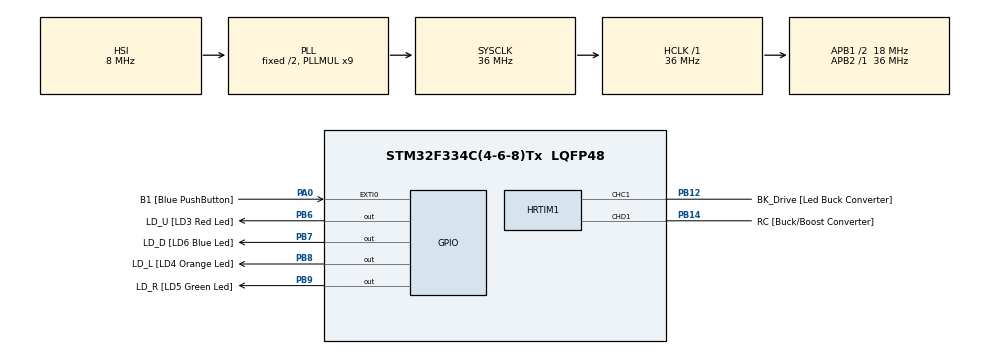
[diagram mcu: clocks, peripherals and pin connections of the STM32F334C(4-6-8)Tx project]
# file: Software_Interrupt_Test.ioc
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HRTIM1.DMARequests_Semaphore-Output_TC1=ATLEASTONEDMAREQ
HRTIM1.DMARequests_Semaphore-Output_TD1=ATLEASTONEDMAREQ
HRTIM1.Output1-Output_TC1=HRTIM_OUTPUT_TC1
HRTIM1.TimerIdx-Output_TC1=HRTIM_TIMERINDEX_TIMER_C
Mcu.Family=STM32F3
Mcu.Name=STM32F334C(4-6-8)Tx
Mcu.Package=LQFP48
NVIC.PriorityGroup=NVIC_PRIORITYGROUP_0
PA0.GPIO_Label=B1 [Blue PushButton]
PA0.GPIO_ModeDefaultEXTI=GPIO_MODE_EVT_RISING
PA0.GPIO_PuPd=GPIO_NOPULL
PA0.Signal=GPXTI0
PA13.GPIO_Label=SWDIO
PA13.Mode=Serial_Wire
PA13.Signal=SYS_JTMS-SWDIO
PA14.GPIO_Label=SWCLK
PA14.Mode=Serial_Wire
PA14.Signal=SYS_JTCK-SWCLK
PB12.GPIO_Label=BK_Drive [Led Buck Converter]
PB12.GPIO_ModeDefaultPP=GPIO_MODE_AF_PP
PB12.GPIO_PuPd=GPIO_NOPULL
PB12.GPIO_Speed=GPIO_SPEED_FREQ_LOW
PB12.Mode=Output_TC1
PB12.Signal=HRTIM1_CHC1
PB14.GPIO_Label=RC [Buck/Boost Converter]
PB14.Mode=Output_TD1
PB14.Signal=HRTIM1_CHD1
PB6.GPIO_FM6=__NULL
PB6.GPIO_Label=LD_U [LD3 Red Led]
PB6.GPIO_ModeDefaultOutputPP=GPIO_MODE_OUTPUT_PP
PB6.GPIO_PuPd=GPIO_NOPULL
PB6.GPIO_Speed=GPIO_SPEED_FREQ_LOW
PB6.Signal=GPIO_Output
PB7.GPIO_FM7=__NULL
PB7.GPIO_Label=LD_D [LD6 Blue Led]
PB7.GPIO_ModeDefaultOutputPP=GPIO_MODE_OUTPUT_PP
PB7.GPIO_PuPd=GPIO_NOPULL
PB7.GPIO_Speed=GPIO_SPEED_FREQ_LOW
PB7.Signal=GPIO_Output
PB8.GPIO_FM8=__NULL
PB8.GPIO_Label=LD_L [LD4 Orange Led]
PB8.GPIO_ModeDefaultOutputPP=GPIO_MODE_OUTPUT_PP
PB8.GPIO_PuPd=GPIO_NOPULL
PB8.GPIO_Speed=GPIO_SPEED_FREQ_LOW
PB8.Signal=GPIO_Output
PB9.GPIO_FM9=__NULL
PB9.GPIO_Label=LD_R [LD5 Green Led]
PB9.GPIO_ModeDefaultOutputPP=GPIO_MODE_OUTPUT_PP
PB9.GPIO_PuPd=GPIO_NOPULL
PB9.GPIO_Speed=GPIO_SPEED_FREQ_LOW
PB9.Signal=GPIO_Output
ProjectManager.HeapSize=0x200
ProjectManager.StackSize=0x400
ProjectManager.TargetToolchain=Makefile
RCC.AHBFreq_Value=36000000
RCC.APB1CLKDivider=RCC_HCLK_DIV2
RCC.APB1Freq_Value=18000000
RCC.APB1TimFreq_Value=36000000
RCC.APB2Freq_Value=36000000
RCC.APB2TimFreq_Value=36000000
RCC.CortexFreq_Value=36000000
RCC.HCLKFreq_Value=36000000
RCC.HSE_VALUE=8000000
RCC.HSI_VALUE=8000000
RCC.LSE_VALUE=32768
RCC.PLLMUL=RCC_PLL_MUL9
RCC.SYSCLKFreq_VALUE=36000000
RCC.SYSCLKSourceVirtual=RCC_SYSCLKSOURCE_PLLCLK
board=32F3348DISCOVERY

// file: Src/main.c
/* USER CODE BEGIN Header */
/**
  ******************************************************************************
  * @file           : main.c
  * @brief          : Main program body
  ******************************************************************************
  ** This notice applies to any and all portions of this file
  * that are not between comment pairs USER CODE BEGIN and
  * USER CODE END. Other portions of this file, whether
  * inserted by the user or by software development tools
  * are owned by their respective copyright owners.
  *
  * COPYRIGHT(c) 2019 STMicroelectronics
  *
  * Redistribution and use in source and binary forms, with or without modification,
  * are permitted provided that the following conditions are met:
  *   1. Redistributions of source code must retain the above copyright notice,
  *      this list of conditions and the following disclaimer.
  *   2. Redistributions in binary form must reproduce the above copyright notice,
  *      this list of conditions and the following disclaimer in the documentation
  *      and/or other materials provided with the distribution.
  *   3. Neither the name of STMicroelectronics nor the names of its contributors
  *      may be used to endorse or promote products derived from this software
  *      without specific prior written permission.
  *
  * THIS SOFTWARE IS PROVIDED BY THE COPYRIGHT HOLDERS AND CONTRIBUTORS "AS IS"
  * AND ANY EXPRESS OR IMPLIED WARRANTIES, INCLUDING, BUT NOT LIMITED TO, THE
  * IMPLIED WARRANTIES OF MERCHANTABILITY AND FITNESS FOR A PARTICULAR PURPOSE ARE
  * DISCLAIMED. IN NO EVENT SHALL THE COPYRIGHT HOLDER OR CONTRIBUTORS BE LIABLE
  * FOR ANY DIRECT, INDIRECT, INCIDENTAL, SPECIAL, EXEMPLARY, OR CONSEQUENTIAL
  * DAMAGES (INCLUDING, BUT NOT LIMITED TO, PROCUREMENT OF SUBSTITUTE GOODS OR
  * SERVICES; LOSS OF USE, DATA, OR PROFITS; OR BUSINESS INTERRUPTION) HOWEVER
  * CAUSED AND ON ANY THEORY OF LIABILITY, WHETHER IN CONTRACT, STRICT LIABILITY,
  * OR TORT (INCLUDING NEGLIGENCE OR OTHERWISE) ARISING IN ANY WAY OUT OF THE USE
  * OF THIS SOFTWARE, EVEN IF ADVISED OF THE POSSIBILITY OF SUCH DAMAGE.
  *
  ******************************************************************************
  */
/* USER CODE END Header */

#include "main.h"

HRTIM_HandleTypeDef hhrtim1;

void SystemClock_Config(void);
static void MX_GPIO_Init(void);
static void MX_HRTIM1_Init(void);
static void EXTI1_Init(void);

int main(void)
{

  /* MCU Configuration--------------------------------------------------------*/

  /* Reset of all peripherals, Initializes the Flash interface and the Systick. */
  HAL_Init();
  EXTI1_Init();

  /* Configure the system clock */
  SystemClock_Config();

  /* Initialize all configured peripherals */
  MX_GPIO_Init();
  MX_HRTIM1_Init();

  /* Infinite loop */
  /* USER CODE BEGIN WHILE */
  while (1)
  {
    //Triggers the External Interrupt on line 1, which takes us to the interrupt handler.
    NVIC->STIR = EXTI1_IRQn;
    HAL_GPIO_TogglePin(GPIOB,LD_D_Pin);
    HAL_Delay(500);
  }
  /* USER CODE END 3 */
}

void SystemClock_Config(void)
{
  RCC_OscInitTypeDef RCC_OscInitStruct = {0};
  RCC_ClkInitTypeDef RCC_ClkInitStruct = {0};
  RCC_PeriphCLKInitTypeDef PeriphClkInit = {0};

  /**Initializes the CPU, AHB and APB busses clocks
  */
  RCC_OscInitStruct.OscillatorType = RCC_OSCILLATORTYPE_HSI;
  RCC_OscInitStruct.HSIState = RCC_HSI_ON;
  RCC_OscInitStruct.HSICalibrationValue = RCC_HSICALIBRATION_DEFAULT;
  RCC_OscInitStruct.PLL.PLLState = RCC_PLL_ON;
  RCC_OscInitStruct.PLL.PLLSource = RCC_PLLSOURCE_HSI;
  RCC_OscInitStruct.PLL.PLLMUL = RCC_PLL_MUL9;
  if (HAL_RCC_OscConfig(&RCC_OscInitStruct) != HAL_OK)
  {
    Error_Handler();
  }
  /**Initializes the CPU, AHB and APB busses clocks
  */
  RCC_ClkInitStruct.ClockType = RCC_CLOCKTYPE_HCLK|RCC_CLOCKTYPE_SYSCLK
                              |RCC_CLOCKTYPE_PCLK1|RCC_CLOCKTYPE_PCLK2;
  RCC_ClkInitStruct.SYSCLKSource = RCC_SYSCLKSOURCE_PLLCLK;
  RCC_ClkInitStruct.AHBCLKDivider = RCC_SYSCLK_DIV1;
  RCC_ClkInitStruct.APB1CLKDivider = RCC_HCLK_DIV2;
  RCC_ClkInitStruct.APB2CLKDivider = RCC_HCLK_DIV1;

  if (HAL_RCC_ClockConfig(&RCC_ClkInitStruct, FLASH_LATENCY_1) != HAL_OK)
  {
    Error_Handler();
  }
  PeriphClkInit.PeriphClockSelection = RCC_PERIPHCLK_HRTIM1;
  PeriphClkInit.Hrtim1ClockSelection = RCC_HRTIM1CLK_HCLK;
  if (HAL_RCCEx_PeriphCLKConfig(&PeriphClkInit) != HAL_OK)
  {
    Error_Handler();
  }
}

static void MX_HRTIM1_Init(void)
{

  HRTIM_TimeBaseCfgTypeDef pTimeBaseCfg = {0};
  HRTIM_TimerCfgTypeDef pTimerCfg = {0};
  HRTIM_OutputCfgTypeDef pOutputCfg = {0};

  hhrtim1.Instance = HRTIM1;
  hhrtim1.Init.HRTIMInterruptResquests = HRTIM_IT_NONE;
  hhrtim1.Init.SyncOptions = HRTIM_SYNCOPTION_NONE;
  if (HAL_HRTIM_Init(&hhrtim1) != HAL_OK)
  {
    Error_Handler();
  }
  pTimeBaseCfg.Period = 0xFFFD;
  pTimeBaseCfg.RepetitionCounter = 0x00;
  pTimeBaseCfg.PrescalerRatio = HRTIM_PRESCALERRATIO_DIV1;
  pTimeBaseCfg.Mode = HRTIM_MODE_CONTINUOUS;
  if (HAL_HRTIM_TimeBaseConfig(&hhrtim1, HRTIM_TIMERINDEX_TIMER_C, &pTimeBaseCfg) != HAL_OK)
  {
    Error_Handler();
  }
  pTimerCfg.InterruptRequests = HRTIM_TIM_IT_NONE;
  pTimerCfg.DMARequests = HRTIM_TIM_DMA_NONE;
  pTimerCfg.DMASrcAddress = 0x0000;
  pTimerCfg.DMADstAddress = 0x0000;
  pTimerCfg.DMASize = 0x1;
  pTimerCfg.HalfModeEnable = HRTIM_HALFMODE_DISABLED;
  pTimerCfg.StartOnSync = HRTIM_SYNCSTART_DISABLED;
  pTimerCfg.ResetOnSync = HRTIM_SYNCRESET_DISABLED;
  pTimerCfg.DACSynchro = HRTIM_DACSYNC_NONE;
  pTimerCfg.PreloadEnable = HRTIM_PRELOAD_DISABLED;
  pTimerCfg.UpdateGating = HRTIM_UPDATEGATING_INDEPENDENT;
  pTimerCfg.BurstMode = HRTIM_TIMERBURSTMODE_MAINTAINCLOCK;
  pTimerCfg.RepetitionUpdate = HRTIM_UPDATEONREPETITION_DISABLED;
  pTimerCfg.PushPull = HRTIM_TIMPUSHPULLMODE_DISABLED;
  pTimerCfg.FaultEnable = HRTIM_TIMFAULTENABLE_NONE;
  pTimerCfg.FaultLock = HRTIM_TIMFAULTLOCK_READWRITE;
  pTimerCfg.DeadTimeInsertion = HRTIM_TIMDEADTIMEINSERTION_DISABLED;
  pTimerCfg.DelayedProtectionMode = HRTIM_TIMER_A_B_C_DELAYEDPROTECTION_DISABLED;
  pTimerCfg.UpdateTrigger = HRTIM_TIMUPDATETRIGGER_NONE;
  pTimerCfg.ResetTrigger = HRTIM_TIMRESETTRIGGER_NONE;
  pTimerCfg.ResetUpdate = HRTIM_TIMUPDATEONRESET_DISABLED;
  if (HAL_HRTIM_WaveformTimerConfig(&hhrtim1, HRTIM_TIMERINDEX_TIMER_C, &pTimerCfg) != HAL_OK)
  {
    Error_Handler();
  }
  pTimerCfg.DMASrcAddress = 0x0000;
  pTimerCfg.DMADstAddress = 0x0000;
  pTimerCfg.DMASize = 0x1;
  pTimerCfg.DelayedProtectionMode = HRTIM_TIMER_D_E_DELAYEDPROTECTION_DISABLED;
  if (HAL_HRTIM_WaveformTimerConfig(&hhrtim1, HRTIM_TIMERINDEX_TIMER_D, &pTimerCfg) != HAL_OK)
  {
    Error_Handler();
  }
  pOutputCfg.Polarity = HRTIM_OUTPUTPOLARITY_HIGH;
  pOutputCfg.SetSource = HRTIM_OUTPUTSET_NONE;
  pOutputCfg.ResetSource = HRTIM_OUTPUTRESET_NONE;
  pOutputCfg.IdleMode = HRTIM_OUTPUTIDLEMODE_NONE;
  pOutputCfg.IdleLevel = HRTIM_OUTPUTIDLELEVEL_INACTIVE;
  pOutputCfg.FaultLevel = HRTIM_OUTPUTFAULTLEVEL_NONE;
  pOutputCfg.ChopperModeEnable = HRTIM_OUTPUTCHOPPERMODE_DISABLED;
  pOutputCfg.BurstModeEntryDelayed = HRTIM_OUTPUTBURSTMODEENTRY_REGULAR;
  if (HAL_HRTIM_WaveformOutputConfig(&hhrtim1, HRTIM_TIMERINDEX_TIMER_C, HRTIM_OUTPUT_TC1, &pOutputCfg) != HAL_OK)
  {
    Error_Handler();
  }
  if (HAL_HRTIM_WaveformOutputConfig(&hhrtim1, HRTIM_TIMERINDEX_TIMER_D, HRTIM_OUTPUT_TD1, &pOutputCfg) != HAL_OK)
  {
    Error_Handler();
  }
  if (HAL_HRTIM_TimeBaseConfig(&hhrtim1, HRTIM_TIMERINDEX_TIMER_D, &pTimeBaseCfg) != HAL_OK)
  {
    Error_Handler();
  }
  HAL_HRTIM_MspPostInit(&hhrtim1);

}

static void MX_GPIO_Init(void)
{
  GPIO_InitTypeDef GPIO_InitStruct = {0};

  /* GPIO Ports Clock Enable */
  __HAL_RCC_GPIOA_CLK_ENABLE();
  __HAL_RCC_GPIOB_CLK_ENABLE();

  /*Configure GPIO pin Output Level */
  HAL_GPIO_WritePin(GPIOB, LD_U_Pin|LD_D_Pin|LD_L_Pin|LD_R_Pin, GPIO_PIN_RESET);

  /*Configure GPIO pin : B1_Pin */
  GPIO_InitStruct.Pin = B1_Pin;
  GPIO_InitStruct.Mode = GPIO_MODE_EVT_RISING;
  GPIO_InitStruct.Pull = GPIO_NOPULL;
  HAL_GPIO_Init(B1_GPIO_Port, &GPIO_InitStruct);

  /*Configure GPIO pins : LD_U_Pin LD_D_Pin LD_L_Pin LD_R_Pin */
  GPIO_InitStruct.Pin = LD_U_Pin|LD_D_Pin|LD_L_Pin|LD_R_Pin;
  GPIO_InitStruct.Mode = GPIO_MODE_OUTPUT_PP;
  GPIO_InitStruct.Pull = GPIO_NOPULL;
  GPIO_InitStruct.Speed = GPIO_SPEED_FREQ_LOW;
  HAL_GPIO_Init(GPIOB, &GPIO_InitStruct);

}

/* USER CODE BEGIN 4 */
static void EXTI1_Init(void)
{
  /* EXTI1 Interrupt Initialization */
  HAL_NVIC_SetPriority(EXTI1_IRQn,1,0);
  HAL_NVIC_EnableIRQ(EXTI1_IRQn);
  LL_EXTI_EnableIT_0_31(LL_EXTI_LINE_1);
  LL_EXTI_EnableRisingTrig_0_31(LL_EXTI_LINE_1);
}
/* USER CODE END 4 */

void Error_Handler(void)
{
}

/************************ (C) COPYRIGHT STMicroelectronics *****END OF FILE****/
